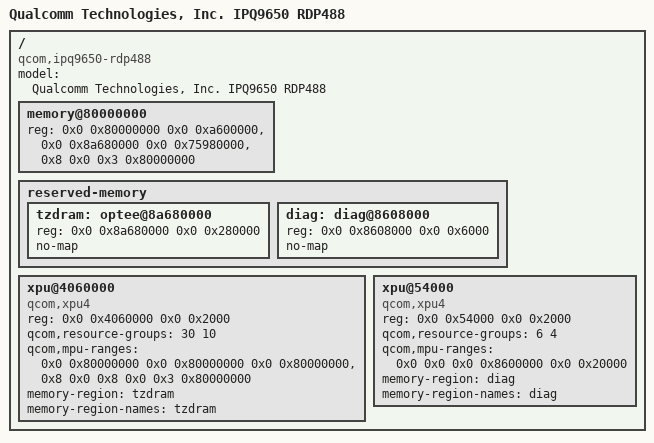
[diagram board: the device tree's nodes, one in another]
// SPDX-License-Identifier: BSD-3-Clause
/*
 * Copyright (c) Qualcomm Technologies, Inc. and/or its subsidiaries.
 *
 * IPQ9650 RDP488 as seen by OP-TEE: only what OP-TEE uses is described.
 */

/dts-v1/;

/ {
	compatible = "qcom,ipq9650-rdp488", "qcom,ipq9650";
	model = "Qualcomm Technologies, Inc. IPQ9650 RDP488";
	#address-cells = <2>;
	#size-cells = <2>;

	/*
	 * The DRAM, without the BL31 of TF-A: 0.5 MB at 0x8a600000, right
	 * below the memory OP-TEE runs from.
	 */
	memory@80000000 {
		device_type = "memory";
		reg = <0x0 0x80000000 0x0 0xa600000>,
		      <0x0 0x8a680000 0x0 0x75980000>,
		      <0x8 0x0 0x3 0x80000000>;
	};

	reserved-memory {
		#address-cells = <2>;
		#size-cells = <2>;
		ranges;

		/* The memory OP-TEE runs from */
		tzdram: optee@8a680000 {
			reg = <0x0 0x8a680000 0x0 0x280000>;
			no-map;
		};

		/* The buffer of the DIAG log, which is in the IMEM */
		diag: diag@8608000 {
			reg = <0x0 0x8608000 0x0 0x6000>;
			no-map;
		};
	};

	/* MACHX_LLCC_MPU */
	xpu@4060000 {
		compatible = "qcom,xpu4";
		reg = <0x0 0x4060000 0x0 0x2000>;
		qcom,resource-groups = <30 10>;
		/* The unit uses the physical addresses of the two DRAM banks */
		qcom,mpu-ranges = <0x0 0x80000000 0x0 0x80000000 0x0 0x80000000>,
				  <0x8 0x0 0x8 0x0 0x3 0x80000000>;
		memory-region = <&tzdram>;
		memory-region-names = "tzdram";
		#access-controller-cells = <2>;
	};

	/* OCIMEM_MPU */
	xpu@54000 {
		compatible = "qcom,xpu4";
		reg = <0x0 0x54000 0x0 0x2000>;
		qcom,resource-groups = <6 4>;
		/* The unit has the IMEM from address 0 */
		qcom,mpu-ranges = <0x0 0x0 0x0 0x8600000 0x0 0x20000>;
		memory-region = <&diag>;
		memory-region-names = "diag";
		#access-controller-cells = <2>;
	};
};
